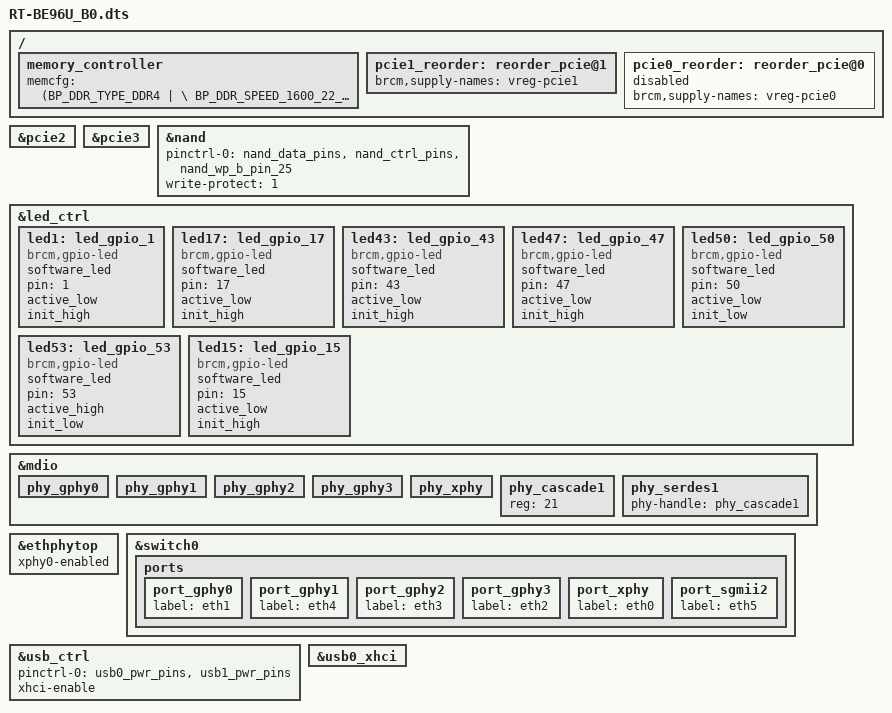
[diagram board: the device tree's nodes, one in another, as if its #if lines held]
#include "6813.dtsi"

/ {
	memory_controller {
		memcfg = <(BP_DDR_TYPE_DDR4       | \
			BP_DDR_SPEED_1600_22_22_22    | \
			BP_DDR_TOTAL_SIZE_2048MB      | \
			BP_DDR_DEVICE_WIDTH_16        | \
			BP_DDR_TOTAL_WIDTH_32BIT      | \
			BP_DDR_TEMP_EXTENDED_ASR      | \
			BP_DDR_SSC_CONFIG_1)>;
	};
/*
    buttons: buttons {
        compatible = "brcm,buttons";
        reset_button {
            ext_irq = <&bca_extintr 13 GPIO_ACTIVE_LOW (BCA_EXTINTR_TYPE_LOW_LEVEL | BCA_EXTINTR_TYPE_SENSE_EDGE)>;
            press {
                print = "Button Press -- Hold for 5s to do restore to default";
            };
            hold {
                rst_to_dflt = <5>;
            };
            release {
                reset = <0>;
            };
        };
        ses_button {
            ext_irq = <&bca_extintr 12 GPIO_ACTIVE_LOW (BCA_EXTINTR_TYPE_LOW_LEVEL | BCA_EXTINTR_TYPE_SENSE_EDGE)>;
            release {
                ses_short_period = <0>;
                ses_long_period = <3>;
            };
        };
    };
*/
};

#if defined(CONFIG_BCM_PCIE_HCD) || defined(CONFIG_BCM_PCIE_HCD_MODULE)
#if defined(CONFIG_REGULATOR) && defined(CONFIG_REGULATOR_FIXED_VOLTAGE)
/**********************************************************************/
/* GPIO: Add one define per GPIO (individual or shared) regulator     */
/*       - Skip if no GPIO regulators in use                          */
/**********************************************************************/
#define PCIE0_REG_GPIO    78    /* SLEEP_0 for vreg_pcie0 node */
#define PCIE1_REG_GPIO    75    /* SLEEP_1 for vreg_pcie1 node */
#define PCIE2_REG_GPIO    76    /* SLEEP_2 for vreg_pcie2 node */
#define PCIE3_REG_GPIO    19    /* SLEEP_3 for vreg_pcie3 node */

#include "../bcm_wlan_regulator.dtsi"

/delete-node/ &pcie0;
/delete-node/ &pcie1;

/ {
    /* pcie core 1 */
    pcie1_reorder: reorder_pcie@1 {
        #define PCIE_ID				1
        #define PCIE_SPI			69
        #define PCIE_ADDR			0x80090000
        #define PCIE_SIZE			PCIE1_REG_SIZE
        #define PCIE_RANGE_ADDR			0xD0000000
        #define PCIE_RANGE_SIZE			0x10000000
        #include "../ip/bcm_pcie_core.dtsi"
    };
    /* pcie core 0 */
    pcie0_reorder: reorder_pcie@0 {
        #define PCIE_ID				0
        #define PCIE_SPI			68
        #define PCIE_ADDR			0x80080000
        #define PCIE_SIZE			0x0000A000
        #define PCIE_RANGE_ADDR			0xC0000000
        #define PCIE_RANGE_SIZE			0x10000000
        #include "../ip/bcm_pcie_core.dtsi"
    };
};

&pcie0_reorder {
	brcm,supply-names = "vreg-pcie0";
	status = "disabled";
};
 
&pcie1_reorder {
	brcm,supply-names = "vreg-pcie1";
	status = "okay";
};

&pcie2 {
	status = "okay";
};

&pcie3 {
	status = "okay";
};

#else /* !defined(CONFIG_REGULATOR) && !defined(CONFIG_REGULATOR_FIXED_VOLTAGE) */

&pcie0_reorder {
	status = "disabled";
};
&pcie1_reorder {
	status = "okay";
};
&pcie2 {
	status = "okay";
};
&pcie3 {
	status = "okay";
};
#endif //defined(CONFIG_REGULATOR) && defined(CONFIG_REGULATOR_FIXED_VOLTAGE)
#endif //#if defined(CONFIG_BCM_PCIE_HCD) || defined(CONFIG_BCM_PCIE_HCD_MODULE)

&nand {
	pinctrl-0 = <&nand_data_pins &nand_ctrl_pins &nand_wp_b_pin_25>;
	write-protect = <1>;
	status = "okay";
};

&led_ctrl {
	status="okay";

	/* GPIO LED */
	/* LAN LED */
	led1:led_gpio_1 {
		compatible = "brcm,gpio-led";
		software_led;
		pin = <1>;
		active_low;
		init_high;
	};
	/* WAN WHITE LED */
	led17:led_gpio_17 {
		compatible = "brcm,gpio-led";
		software_led;
		pin = <17>;
		active_low;
		init_high;
	};
	/* WAN RED LED */
	led43:led_gpio_43 {
		compatible = "brcm,gpio-led";
		software_led;
		pin = <43>;
		active_low;
		init_high;
	};
	/* 10G LAN LED */
	led47:led_gpio_47 {
		compatible = "brcm,gpio-led";
		software_led;
		pin = <47>;
		active_low;
		init_high;
	};
	/* POWER LED */
	led50:led_gpio_50 {
		compatible = "brcm,gpio-led";
		software_led;
		pin = <50>;
		active_low;
		init_low;
	};
	/* WPS LED */
	led53:led_gpio_53 {
		compatible = "brcm,gpio-led";
		software_led;
		pin = <53>;
		active_high;
		init_low;
	};
	/* AFC LED */
	led15:led_gpio_15 {
		compatible = "brcm,gpio-led";
		software_led;
		pin = <15>;
		active_low;
		init_high;
	};
};

/* For AURA72UB0, NP for now
&i2c1 {
	pinctrl-names = "default";
	pinctrl-0 = <&i2c1_sclk_pin_14 &i2c1_sdata_pin_15>;
	status = "okay";
};
*/

&mdio {
    /* Port PHY mapping:
        port_gphy0 <----> phy_gphy0
        port_gphy1 <----> phy_gphy1
        port_gphy2 <----> phy_gphy2
        port_gphy3 <----> phy_gphy3
        port_xphy <-----> phy_xphy      - Internal 10G PHY
        port_sgmii1 <---> phy_serdes0   - BCM84891L
        port_sgmii2 <---> phy_serdes1   - BCM84891L
     */
	phy_gphy0 {
		status = "okay";
	};

	phy_gphy1 {
		status = "okay";
	};

	phy_gphy2 {
		status = "okay";
	};

	phy_gphy3 {
		status = "okay";
	};

	phy_xphy {
		status = "okay";
	};

    /* Disable SGMII-1/BCM84891L, not installed
    phy_cascade0 {
        reg = <19>;
		status = "okay";
	};

	phy_serdes0 {
		phy-handle = <&phy_cascade0>;
		status = "okay";
	};
    */

    phy_cascade1 {
        reg = <21>;
		status = "okay";
	};

	phy_serdes1 {
		phy-handle = <&phy_cascade1>;
		status = "okay";
	};
};

&ethphytop {
    xphy0-enabled;
    status = "okay";
};

&switch0 {
	ports {
		port_gphy0 {
			status = "okay";
			label = "eth1";
		};

		port_gphy1 {
			status = "okay";
			label = "eth4";
		};

		port_gphy2 {
			status = "okay";
			label = "eth3";
		};

		port_gphy3 {
			status = "okay";
			label = "eth2";
		};

		port_xphy {
			status = "okay";
			label = "eth0";
		};

        /* Disable SGMII-1/BCM84891L, not installed
		port_sgmii1 {
			status = "okay";
		};
        */

		port_sgmii2 {
			status = "okay";
			label = "eth5";
		};
	};
};

&usb_ctrl {
	pinctrl-names = "default";
	pinctrl-0 = <&usb0_pwr_pins &usb1_pwr_pins>;
	status = "okay";
	xhci-enable;
};
&usb0_xhci {
	status = "okay";
};
